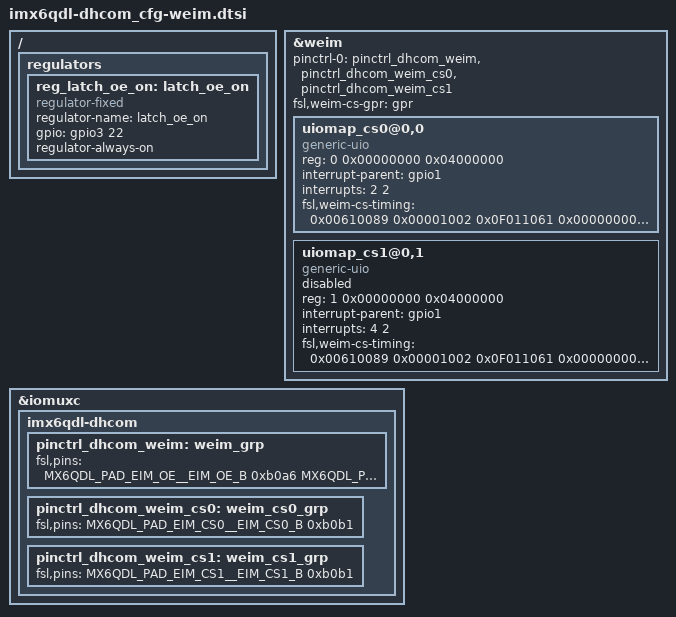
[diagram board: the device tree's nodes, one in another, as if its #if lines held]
/*
 * Copyright 2015 DH electronics GmbH
 *
 * The code contained herein is licensed under the GNU General Public
 * License. You may obtain a copy of the GNU General Public License
 * Version 2 or later at the following locations:
 *
 * http://www.opensource.org/licenses/gpl-license.html
 * http://www.gnu.org/copyleft/gpl.html
 */

/ {
	regulators {
		reg_latch_oe_on: latch_oe_on {
			compatible = "regulator-fixed";
			regulator-name = "latch_oe_on";
			#ifdef DHCOM_HW200
				gpio = <&gpio6 30 0>;				// GPIO 6.30: LATCH_OE (#190)
			#endif
			#ifdef DHCOM_HW300
				gpio = <&gpio3 22 0>;				// GPIO 3.22: LATCH_OE (#86)
			#endif
			//enable-active-high;					// Polarity of GPIO: Active low ==> Disable this property
			regulator-always-on;
		};
	};
};

&weim {
	pinctrl-names = "default";
	pinctrl-0 = <&pinctrl_dhcom_weim &pinctrl_dhcom_weim_cs0 &pinctrl_dhcom_weim_cs1>;
	#address-cells = <2>;
	#size-cells = <1>;
	/* it is necessary to setup 2x 64MB otherwise setting gpr fails */
	ranges = <0 0  0x08000000  0x04000000>,					// Chip select 0 == DHCOM CS A
		 <1 0  0x0c000000  0x04000000>;					// Chip select 1 == DHCOM CS B
	fsl,weim-cs-gpr = <&gpr>;
	status = "okay";

	uiomap_cs0@0,0 {
		compatible = "generic-uio";
		reg = <0 0x00000000 0x04000000>;
		reg-names = "uio_cs0";
		interrupt-parent = <&gpio1>;
		interrupts = <2 2>;						// Add gpio A == interrupt
		#address-cells = <1>;
		#size-cells = <1>;
		fsl,weim-cs-timing = <0x00610089 0x00001002 0x0F011061
				      0x00000000 0x0F068A31 0x00000000>;
		status = "okay";
	};

	uiomap_cs1@0,1 {
		compatible = "generic-uio";
		reg = <1 0x00000000 0x04000000>;
		reg-names = "uio_cs1";
		interrupt-parent = <&gpio1>;
		interrupts = <4 2>;						// Add gpio B == interrupt
		#address-cells = <1>;
		#size-cells = <1>;
		fsl,weim-cs-timing = <0x00610089 0x00001002 0x0F011061
				      0x00000000 0x0F068A31 0x00000000>;
		status = "disabled";
	};
};

&iomuxc {
	imx6qdl-dhcom {
		pinctrl_dhcom_weim: weim_grp {
			fsl,pins = <
				MX6QDL_PAD_EIM_OE__EIM_OE_B         0xb0a6
				MX6QDL_PAD_EIM_RW__EIM_RW           0xb0a6	// Write Enable
				MX6QDL_PAD_EIM_LBA__EIM_LBA_B       0xb060	// Latch Enable (LE)
#ifdef DHCOM_HW200
				MX6QDL_PAD_RGMII_RXC__GPIO6_IO30    0x130B0	// GPIO 6.30: LATCH_OE (#190)
#endif
#ifdef DHCOM_HW300
				MX6QDL_PAD_EIM_D22__GPIO3_IO22      0x130B0	// GPIO 3.22: LATCH_OE (#86)
#endif
				/* address/data lines */
				MX6QDL_PAD_EIM_DA15__EIM_AD15       0xb0a6
				MX6QDL_PAD_EIM_DA14__EIM_AD14       0xb0a6
				MX6QDL_PAD_EIM_DA13__EIM_AD13       0xb0a6
				MX6QDL_PAD_EIM_DA12__EIM_AD12       0xb0a6
				MX6QDL_PAD_EIM_DA11__EIM_AD11       0xb0a6
				MX6QDL_PAD_EIM_DA10__EIM_AD10       0xb0a6
				MX6QDL_PAD_EIM_DA9__EIM_AD09        0xb0a6
				MX6QDL_PAD_EIM_DA8__EIM_AD08        0xb0a6
				MX6QDL_PAD_EIM_DA7__EIM_AD07        0xb0a6
				MX6QDL_PAD_EIM_DA6__EIM_AD06        0xb0a6
				MX6QDL_PAD_EIM_DA5__EIM_AD05        0xb0a6
				MX6QDL_PAD_EIM_DA4__EIM_AD04        0xb0a6
				MX6QDL_PAD_EIM_DA3__EIM_AD03        0xb0a6
				MX6QDL_PAD_EIM_DA2__EIM_AD02        0xb0a6
				MX6QDL_PAD_EIM_DA1__EIM_AD01        0xb0a6
				MX6QDL_PAD_EIM_DA0__EIM_AD00        0xb0a6
			>;
		};

		pinctrl_dhcom_weim_cs0: weim_cs0_grp {
			fsl,pins = <
				MX6QDL_PAD_EIM_CS0__EIM_CS0_B       0xb0b1
			>;
		};

		pinctrl_dhcom_weim_cs1: weim_cs1_grp {
			fsl,pins = <
				MX6QDL_PAD_EIM_CS1__EIM_CS1_B       0xb0b1
			>;
		};
	};
};
